# PIC16F1578 register map
Vendor: Microchip
Registers are 8-bit, read-write, reset 0x0 unless marked. A register's access mark holds for its fields unless they carry their own. Addresses are absolute, and some are shared; only a register's first bit layout is shown; [hi:lo] are bit positions; {n}, {i} and the like mark numbered series.

## SFR
0x00 INDF0 reset not defined — (power-on value xxxxxxxx)
0x01 INDF1 reset not defined — (power-on value xxxxxxxx)
0x02 PCL
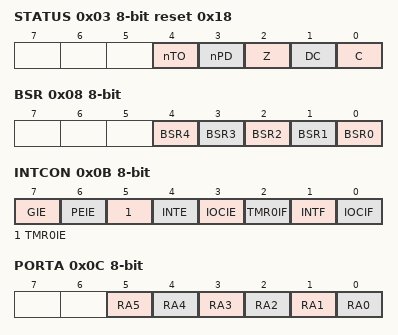
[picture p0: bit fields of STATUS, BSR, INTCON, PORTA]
0x03 STATUS reset 0x18
  [4] nTO ro, [3] nPD ro, [2] Z, [1] DC, [0] C
0x04 FSR0L
0x05 FSR0H
0x06 FSR1L
0x07 FSR1H
0x08 BSR
  [n] BSR{n} (n=0..4)
0x09 WREG
  [7:0] WREG0
0x0A PCLATH
  [6:0] PCLATH
0x0B INTCON
  [7] GIE, [6] PEIE, [5] TMR0IE, [4] INTE, [3] IOCIE, [2] TMR0IF, [1] INTF, [0] IOCIF ro
0x0C PORTA reset not defined — (power-on value --xxxxxx)
  [5] RA5, [4] RA4, [3] RA3 ro, [2] RA2, [1] RA1, [0] RA0
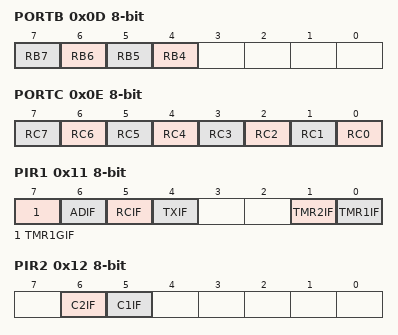
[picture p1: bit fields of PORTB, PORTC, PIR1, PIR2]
0x0D PORTB reset not defined — (power-on value xxxx----)
  [n] RB{n} (n=4..7)
0x0E PORTC reset not defined — (power-on value xxxxxxxx)
  [n] RC{n} (n=0..7)
0x11 PIR1
  [7] TMR1GIF — Timer1 Gate Interrupt Flag bit
  [6] ADIF — A/D Converter Interrupt Flag bit
  [5] RCIF ro — EUSART Receive Interrupt Flag bit
  [4] TXIF ro — EUSART Transmit Interrupt Flag bit
  [1] TMR2IF — TMR2 to PR2 Match Interrupt Flag bit
  [0] TMR1IF — TMR1 Overflow Interrupt Flag bit
0x12 PIR2
  [6] C2IF, [5] C1IF
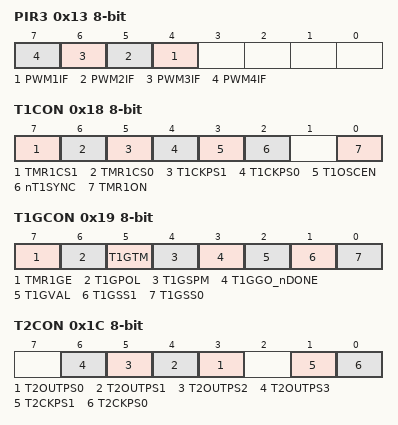
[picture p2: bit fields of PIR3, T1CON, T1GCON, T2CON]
0x13 PIR3
  [n+3] PWM{n}IF (n=1..4)
0x15 TMR0 reset not defined — (power-on value xxxxxxxx)
0x16 TMR1L reset not defined — (power-on value xxxxxxxx)
0x17 TMR1H reset not defined — (power-on value xxxxxxxx)
0x18 T1CON
  [7] TMR1CS1, [6] TMR1CS0, [5] T1CKPS1, [4] T1CKPS0, [3] T1OSCEN, [2] nT1SYNC, [0] TMR1ON
0x19 T1GCON reset not defined — (power-on value 00000x00)
  [7] TMR1GE, [6] T1GPOL, [5] T1GTM, [4] T1GSPM, [3] T1GGO_nDONE, [2] T1GVAL ro, [1] T1GSS1, [0] T1GSS0
0x1A TMR2
0x1B PR2 reset 0xFF
0x1C T2CON
  [n+3] T2OUTPS{n} (n=0..3), [1] T2CKPS1, [0] T2CKPS0
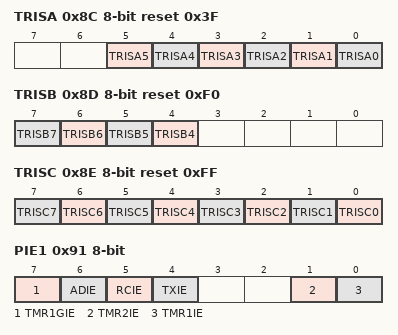
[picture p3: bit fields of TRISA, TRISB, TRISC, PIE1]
0x8C TRISA reset 0x3F — PORTA Data Direction Control Register
  [5] TRISA5, [4] TRISA4, [3] TRISA3 ro, [2] TRISA2, [1] TRISA1, [0] TRISA0
0x8D TRISB reset 0xF0
  [n] TRISB{n} (n=4..7)
0x8E TRISC reset 0xFF — PORTA Data Direction Control Register
  [n] TRISC{n} (n=0..7)
0x91 PIE1 — Peripheral Interrupt Enable Register 1
  [7] TMR1GIE — Timer1 Gate Interrupt Enable bit
  [6] ADIE — A/D Converter Interrupt Enable bit
  [5] RCIE — EUSART Receive Interrupt Enable bit
  [4] TXIE — EUSART Transmit Interrupt Enable bit
  [1] TMR2IE — TMR2 to PR2 Match Interrupt Enable bit
  [0] TMR1IE — TMR1 Overflow Interrupt Enable bit
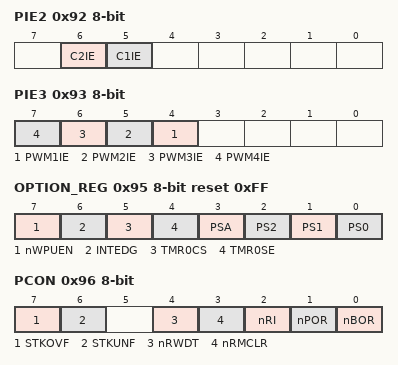
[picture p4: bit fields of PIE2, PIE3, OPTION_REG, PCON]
0x92 PIE2 — Peripheral Interrupt Enable Register 2
  [6] C2IE
  [5] C1IE — Comparator C1 Interrupt Enable bit
0x93 PIE3
  [n+3] PWM{n}IE (n=1..4)
0x95 OPTION_REG reset 0xFF — Option Register
  [7] nWPUEN — Weak Pull-up Enable bit
  [6] INTEDG — Interrupt Edge Select bit
  [5] TMR0CS — TMR0 Clock Source Select bit
  [4] TMR0SE — TMR0 Source Edge Select bit
  [3] PSA — Prescaler Active bit
  [2] PS2 — Prescaler Rate Select bits
  [1] PS1 — Prescaler Rate Select bits
  [0] PS0 — Prescaler Rate Select bits
0x96 PCON reset not defined — Power Control Register (power-on value 00-111qq)
  [7] STKOVF — Stack Overflow Flag bit
  [6] STKUNF — Stack Underflow Flag bit
  [4] nRWDT
  [3] nRMCLR — MCLR Reset Flag bit
  [2] nRI — RESET Instruction Flag bit
  [1] nPOR — Power-on Reset Status bit
  [0] nBOR — Brown-out Reset Status bit
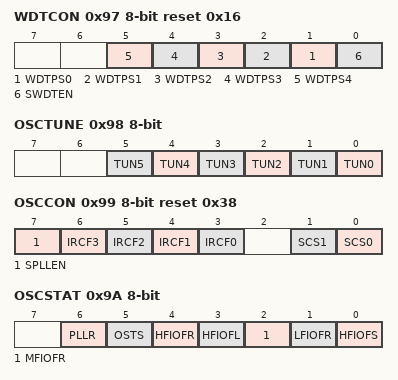
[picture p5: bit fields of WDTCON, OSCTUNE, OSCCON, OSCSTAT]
0x97 WDTCON reset 0x16 — Watchdog Timer Control Register
  [n+1] WDTPS{n} (n=0..4) — Watchdog Timer Period Select bits
  [0] SWDTEN — Software Enable/Disable for Watch Dog Timer bit
0x98 OSCTUNE — Oscillator Tuning Register
  [n] TUN{n} (n=0..5) — Frequency Tuning bits
0x99 OSCCON reset 0x38 — Oscillator Control Register
  [7] SPLLEN — Software PLL Enable bit
  [n+3] IRCF{n} (n=0..3) — Internal Oscillator Frequency Select bits
  [1] SCS1 — System clock select bit
  [0] SCS0 — System clock select bit
0x9A OSCSTAT ro reset not defined — Oscillator Status Register (power-on value -0q00q00)
  [6] PLLR — 4x PLL Ready bit
  [5] OSTS
  [4] HFIOFR — High Freqency Internal Oscillator Ready bit
  [3] HFIOFL — High Freqency Internal Oscillator Status Locked bit
  [2] MFIOFR — Medium Freqency Internal Oscillator Ready bit
  [1] LFIOFR — Low Freqency Internal Oscillator Ready bit
  [0] HFIOFS — Low Freqency Internal Oscillator Ready bit
0x9B ADRESL reset not defined — A/D Result Register LSB (power-on value xxxxxxxx)
0x9C ADRESH reset not defined — A/D Result Register MSB (power-on value xxxxxxxx)
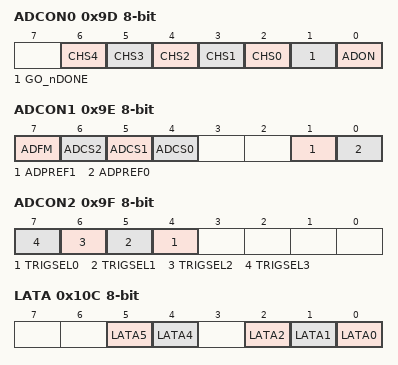
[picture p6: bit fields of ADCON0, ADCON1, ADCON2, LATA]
0x9D ADCON0 reset not defined — Analog-to-Digital Control Register 0 (power-on value -xxx0000)
  [6] CHS4
  [5] CHS3
  [4] CHS2
  [3] CHS1 — Analog Channel Select bits
  [2] CHS0 — Analog Channel Select bits
  [1] GO_nDONE — A/D Conversion Status bit
  [0] ADON — A/D Module Enable bit
0x9E ADCON1 — Analog-to-Digital Control Register 1
  [7] ADFM — A/D Result Format Select bit
  [6] ADCS2 — A/D Conversion Clock Select bits
  [5] ADCS1 — A/D Conversion Clock Select bits
  [4] ADCS0 — A/D Conversion Clock Select bits
  [1] ADPREF1 — A/D Positive Voltage Reference Configuration
  [0] ADPREF0 — A/D Positive Voltage Reference Configuration
0x9F ADCON2
  [n+4] TRIGSEL{n} (n=0..3)
0x10C LATA reset not defined — (power-on value --xx-xxx)
  [5] LATA5, [4] LATA4, [2] LATA2, [1] LATA1, [0] LATA0
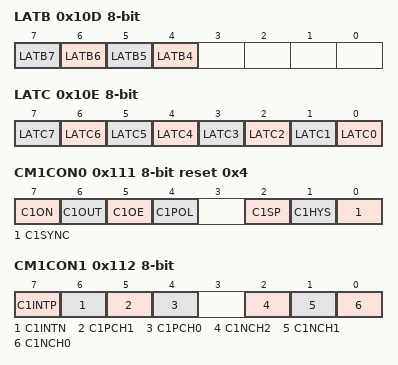
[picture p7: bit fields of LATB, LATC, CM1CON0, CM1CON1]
0x10D LATB reset not defined — (power-on value xxxx----)
  [n] LATB{n} (n=4..7)
0x10E LATC reset not defined — (power-on value xxxxxxxx)
  [n] LATC{n} (n=0..7)
0x111 CM1CON0 reset 0x4
  [7] C1ON — Comparator Enable bit
  [6] C1OUT ro — Comparator Output bit
  [5] C1OE
  [4] C1POL — Comparator Output Polarity Select bit
  [2] C1SP — Comparator Speed/Power Select bit
  [1] C1HYS — Comparator Hysteresis Enable bit
  [0] C1SYNC — Comparator Output Synchronous Mode bit
0x112 CM1CON1
  [7] C1INTP — Comparator Interrupt on Positive going edge Enable bits
  [6] C1INTN — Comparator Interrupt on Negative going edge Enable bits
  [5] C1PCH1 — Comparator Positive Input Channel Select bits
  [4] C1PCH0 — Comparator Positive Input Channel Select bits
  [2] C1NCH2
  [1] C1NCH1
  [0] C1NCH0 — Comparator Negative Input Channel Select bits
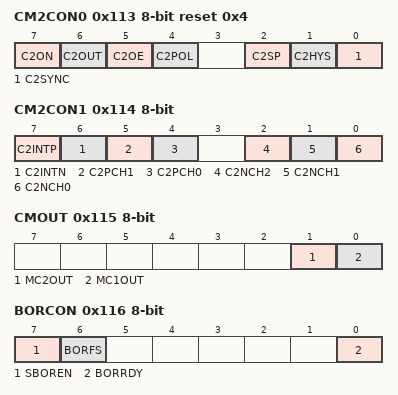
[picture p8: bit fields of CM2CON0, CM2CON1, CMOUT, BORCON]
0x113 CM2CON0 reset 0x4
  [7] C2ON — Comparator Enable bit
  [6] C2OUT ro — Comparator Output bit
  [5] C2OE
  [4] C2POL — Comparator Output Polarity Select bit
  [2] C2SP — Comparator Speed/Power Select bit
  [1] C2HYS — Comparator Hysteresis Enable bit
  [0] C2SYNC — Comparator Output Synchronous Mode bit
0x114 CM2CON1
  [7] C2INTP — Comparator Interrupt on Positive going edge Enable bits
  [6] C2INTN — Comparator Interrupt on Negative going edge Enable bits
  [5] C2PCH1 — Comparator Positive Input Channel Select bits
  [4] C2PCH0 — Comparator Positive Input Channel Select bits
  [2] C2NCH2
  [1] C2NCH1
  [0] C2NCH0 — Comparator Negative Input Channel Select bits
0x115 CMOUT ro — Comparator Output Register
  [1] MC2OUT, [0] MC1OUT
0x116 BORCON reset not defined — Brown-out Reset Control Register (power-on value 10-----q)
  [7] SBOREN — Software Brown Out Reset Enable bit
  [6] BORFS
  [0] BORRDY ro — Brown-out Reset Circuit Ready Status bit
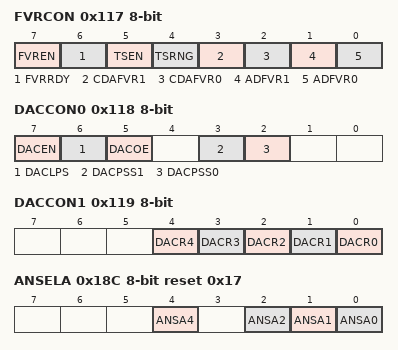
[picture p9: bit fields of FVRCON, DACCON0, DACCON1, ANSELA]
0x117 FVRCON reset not defined — Fixed Voltage Reference Control Register (power-on value 0q000000)
  [7] FVREN — Fixed Voltage Reference Enable
  [6] FVRRDY ro — Fixed Voltage Reference Ready Flag
  [5] TSEN — Temperature Indicator Enable
  [4] TSRNG — Temperature Indicator Range Selection
  [3] CDAFVR1 — Comparator and D/A Converter Fixed Voltage Reference Selection
  [2] CDAFVR0 — Comparator and D/A Converter Fixed Voltage Reference Selection
  [1] ADFVR1 — A/D Converter Fixed Voltage Reference Selection
  [0] ADFVR0 — A/D Converter Fixed Voltage Reference Selection
0x118 DACCON0 — Voltage Reference Control Register 0
  [7] DACEN — DAC 1 Enable bit
  [6] DACLPS — DAC 1 Low Power Voltage State Select bit
  [5] DACOE — DAC1 Voltage Output Enable bit
  [3] DACPSS1 — DAC1 Positive Source Select bits
  [2] DACPSS0 — DAC1 Positive Source Select bits
0x119 DACCON1 — Voltage Reference Control Register 1
  [n] DACR{n} (n=0..4) — DAC1 Voltage Output Select bits
0x18C ANSELA reset 0x17
  [4] ANSA4, [2] ANSA2, [1] ANSA1, [0] ANSA0
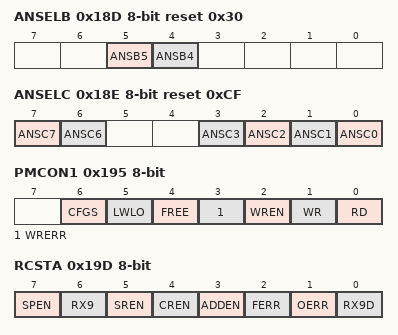
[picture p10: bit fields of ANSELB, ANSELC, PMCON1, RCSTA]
0x18D ANSELB reset 0x30
  [5] ANSB5, [4] ANSB4
0x18E ANSELC reset 0xCF
  [7] ANSC7, [6] ANSC6, [n] ANSC{n} (n=0..3)
0x191 PMADRL
0x192 PMADRH reset 0x80
  [6:0] PMADRH
0x193 PMDATL reset not defined — (power-on value xxxxxxxx)
0x194 PMDATH reset not defined — (power-on value --xxxxxx)
  [5:0] PMDATH
0x195 PMCON1 reset not defined — (power-on value 1000x000)
  [6] CFGS — FLASH Program / Data EEPROM or Configuration Select bit
  [5] LWLO — Load Write Latches Only bit
  [4] FREE — Program FLASH Erase Enable bit
  [3] WRERR — Sequence Error Flag bit
  [2] WREN — Program/Erase Enable bit
  [1] WR — Write Control bit (can only be set)
  [0] RD — Read Control bit (can only be set)
0x196 PMCON2 wo
0x197 VREGCON reset 0x1
  [1] VREGPM
0x199 RCREG ro
0x19A TXREG
0x19B SPBRGL
0x19C SPBRGH
0x19D RCSTA reset not defined — Receive Status and Control Register (power-on value 0000000x)
  [7] SPEN — Serial Port Enable bit
  [6] RX9 — 9-bit Receive Enable bit
  [5] SREN — Single Receive Enable bit
  [4] CREN — Continuous Receive Enable bit
  [3] ADDEN — Address Detect Enable bit
  [2] FERR ro — Framing Error bit
  [1] OERR ro — Overrun Error bit
  [0] RX9D ro — 9th bit of received data (can be parity bit)
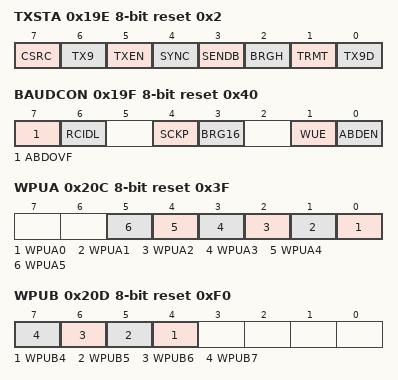
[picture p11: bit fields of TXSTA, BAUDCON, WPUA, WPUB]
0x19E TXSTA reset 0x2 — Transmit Status and Control Register
  [7] CSRC — Clock Source Select bit
  [6] TX9 — 9-bit Transmit Enable bit
  [5] TXEN — Transmit Enable bit
  [4] SYNC — USART Mode Select bit
  [3] SENDB — Send BREAK character bit
  [2] BRGH — High Baud Rate Select bit
  [1] TRMT ro — Transmit Operation Idle Status bit
  [0] TX9D — 9th bit of transmit data; can be used as parity bit
0x19F BAUDCON reset 0x40 — Baud Rate Control Register
  [7] ABDOVF — BRG Rollover Status bit
  [6] RCIDL ro — Receive Operation Idle Status bit
  [4] SCKP — Clock/Transmit Polarity Select bit
  [3] BRG16 — 16-bit Baud Rate Register enable bit
  [1] WUE — Wake-Up Enable bit
  [0] ABDEN — Auto-Baud Detect Enable bit
0x20C WPUA reset 0x3F
  [n] WPUA{n} (n=0..5)
0x20D WPUB reset 0xF0
  [n] WPUB{n} (n=4..7)
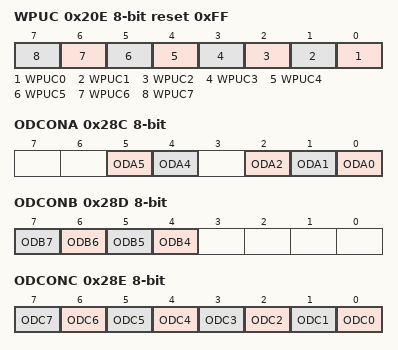
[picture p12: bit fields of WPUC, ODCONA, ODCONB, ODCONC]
0x20E WPUC reset 0xFF
  [n] WPUC{n} (n=0..7)
0x28C ODCONA
  [5] ODA5, [4] ODA4, [2] ODA2, [1] ODA1, [0] ODA0
0x28D ODCONB
  [n] ODB{n} (n=4..7)
0x28E ODCONC
  [n] ODC{n} (n=0..7)
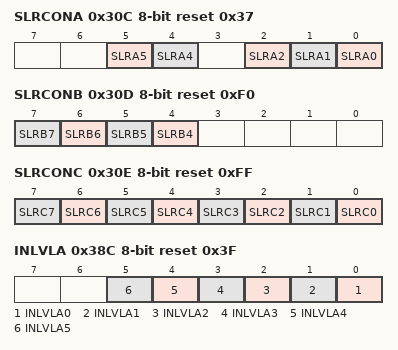
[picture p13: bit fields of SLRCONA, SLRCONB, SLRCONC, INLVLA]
0x30C SLRCONA reset 0x37
  [5] SLRA5, [4] SLRA4, [2] SLRA2, [1] SLRA1, [0] SLRA0
0x30D SLRCONB reset 0xF0
  [n] SLRB{n} (n=4..7)
0x30E SLRCONC reset 0xFF
  [n] SLRC{n} (n=0..7)
0x38C INLVLA reset 0x3F
  [n] INLVLA{n} (n=0..5)
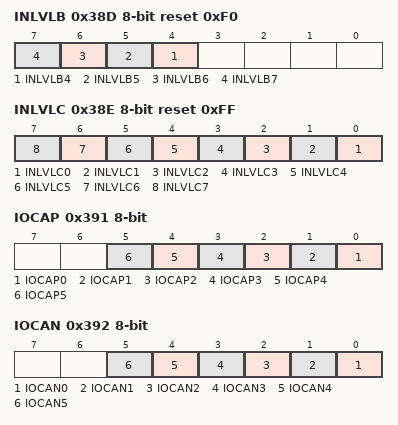
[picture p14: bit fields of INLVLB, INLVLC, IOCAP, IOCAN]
0x38D INLVLB reset 0xF0
  [n] INLVLB{n} (n=4..7)
0x38E INLVLC reset 0xFF
  [n] INLVLC{n} (n=0..7)
0x391 IOCAP — Interrupt-On-Change Positive Edge Register
  [n] IOCAP{n} (n=0..5)
0x392 IOCAN — Interrupt-On-Change Negative Edge Register
  [n] IOCAN{n} (n=0..5)
0x393 IOCAF — Interrupt-On-Change Flag Register
  [n] IOCAF{n} (n=0..5)
0x394 IOCBP — Interrupt-On-Change Positive Edge Register
  [n] IOCBP{n} (n=4..7)
0x395 IOCBN — Interrupt-On-Change Negative Edge Register
  [n] IOCBN{n} (n=4..7)
0x396 IOCBF — Interrupt-On-Change Flag Register
  [n] IOCBF{n} (n=4..7)
0x397 IOCCP — Interrupt-On-Change Positive Edge Register
  [n] IOCCP{n} (n=0..7)
0x398 IOCCN — Interrupt-On-Change Negative Edge Register
  [n] IOCCN{n} (n=0..7)
0x399 IOCCF — Interrupt-On-Change Flag Register
  [n] IOCCF{n} (n=0..7)
0xD8E PWMEN
  [n-1] PWM{n}EN_A (n=1..4)
0xD8F PWMLD
  [n-1] PWM{n}LDA_A (n=1..4)
0xD90 PWMOUT
  [n-1] PWM{n}OUT_A (n=1..4)
0xE0F PPSLOCK
  [0] PPSLOCKED
0xE10 INTPPS reset 0x2
  [4:0] INTPPS
0xE11 T0CKIPPS reset 0x2
  [4:0] T0CKIPPS
0xE12 T1CKIPPS reset 0x5
  [4:0] T1CKIPPS
0xE13 T1GPPS reset 0x4
  [4:0] T1GPPS
0xE14 CWG1INPPS reset 0x2
  [4:0] CWG1INPPS
0xE15 RXPPS reset 0x15
  [4:0] RXPPS
0xE16 CKPPS reset 0x14
  [4:0] CKPPS
0xE17 ADCACTPPS reset 0x14
  [4:0] ADCACTPPS
{0xE90+i} RA{i}PPS (i=0..2)
  [3:0] RA{i}PPS
0xE94 RA4PPS
  [3:0] RA4PPS
0xE95 RA5PPS
  [3:0] RA5PPS
{0xE98+i} RB{i}PPS (i=4..7)
  [3:0] RB{i}PPS
{0xEA0+i} RC{i}PPS (i=0..7)
  [3:0] RC{i}PPS
0xFE4 STATUS_SHAD reset not defined — (power-on value -----xxx)
  [2] Z_SHAD, [1] DC_SHAD, [0] C_SHAD
0xFE5 WREG_SHAD reset not defined — (power-on value xxxxxxxx)
0xFE6 BSR_SHAD reset not defined — (power-on value ---xxxxx)
  [4:0] BSR_SHAD
0xFE7 PCLATH_SHAD reset not defined — (power-on value -xxxxxxx)
  [6:0] PCLATH_SHAD
0xFE8 FSR0L_SHAD reset not defined — (power-on value xxxxxxxx)
0xFE9 FSR0H_SHAD reset not defined — (power-on value xxxxxxxx)
0xFEA FSR1L_SHAD reset not defined — (power-on value xxxxxxxx)
0xFEB FSR1H_SHAD reset not defined — (power-on value xxxxxxxx)
0xFED STKPTR reset 0x1F — Current Stack pointer
  [4:0] STKPTR
0xFEE TOSL reset not defined — Top of Stack Low byte (power-on value xxxxxxxx)
0xFEF TOSH reset not defined — Top of Stack High byte (power-on value -xxxxxxx)
  [6:0] TOSH
